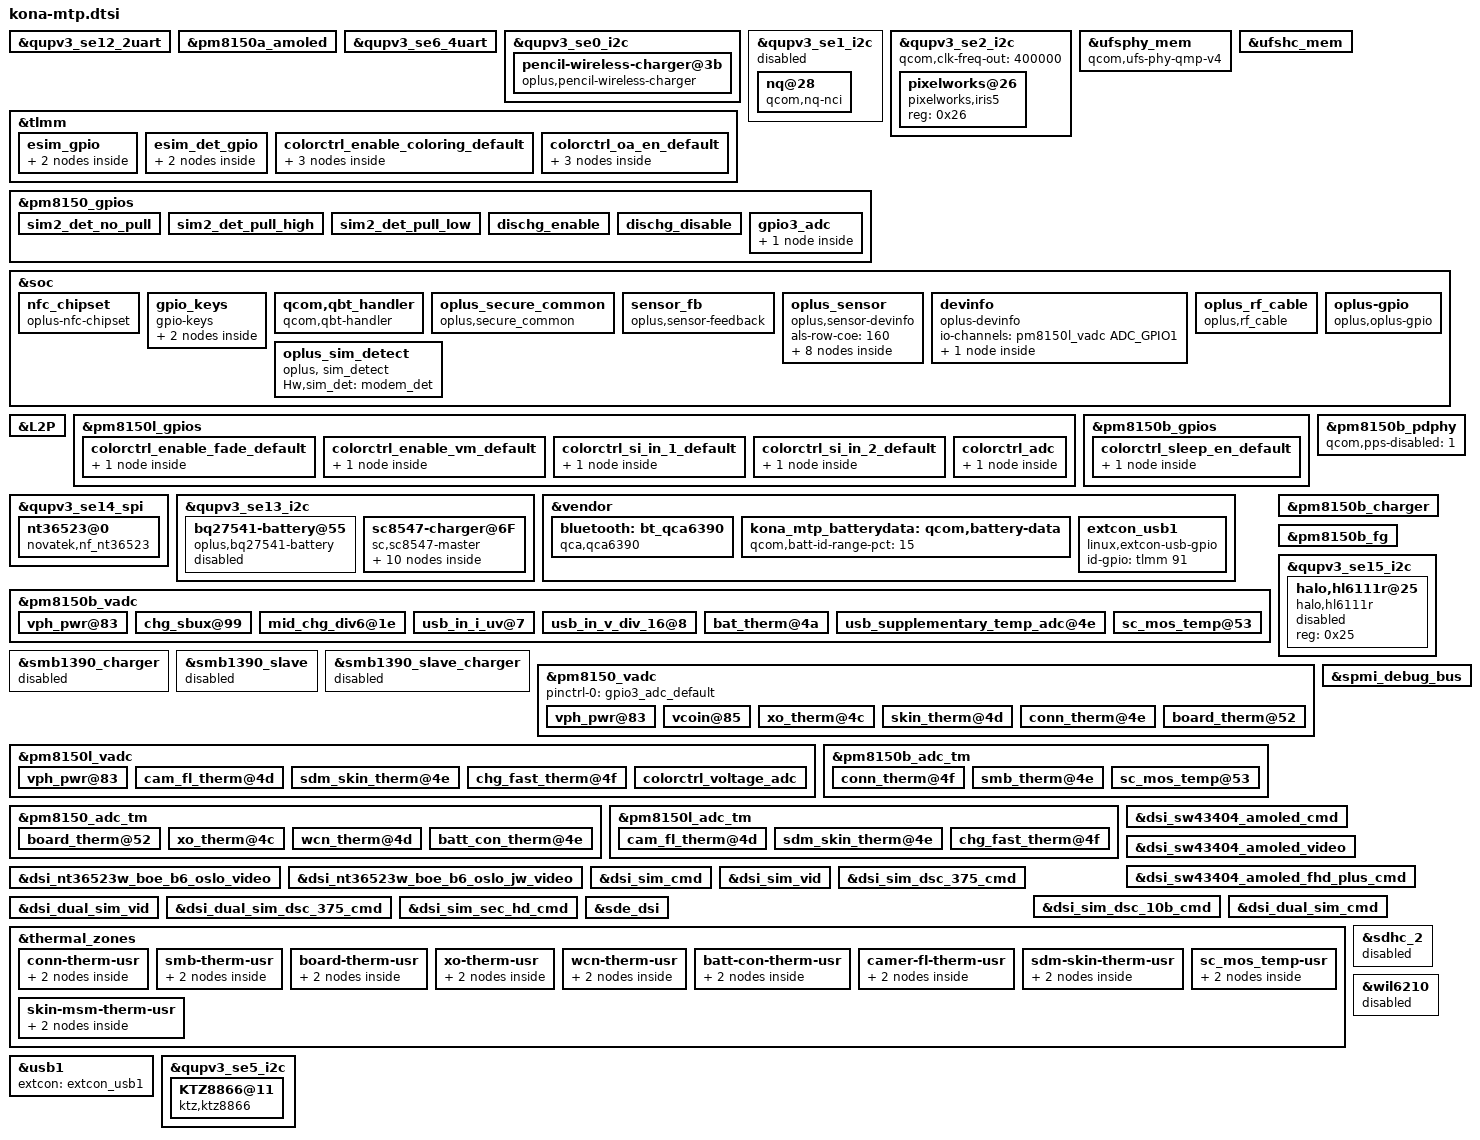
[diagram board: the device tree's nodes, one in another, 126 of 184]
#include <dt-bindings/gpio/gpio.h>
#include <dt-bindings/input/input.h>

#include "kona-pmic-overlay.dtsi"
#include "kona-sde-display.dtsi"
#include "camera/kona-camera-sensor-mtp.dtsi"
#include "kona-audio-overlay.dtsi"
#include "kona-thermal-overlay.dtsi"
#include "nt36523_tp_firmware.dtsi"
&qupv3_se12_2uart {
	status = "ok";
};

&pm8150a_amoled {
	status = "ok";
};

&qupv3_se6_4uart {
	status = "ok";
};
/* #ifdef OPLUS_ARCH_EXTENDS */
/* delete for audio pa
&dai_mi2s2 {
	qcom,msm-mi2s-tx-lines = <1>;
	pinctrl-names = "default", "sleep";
	pinctrl-0 = <&tert_mi2s_sck_active &tert_mi2s_ws_active
			&tert_mi2s_sd0_active>;
	pinctrl-1 = <&tert_mi2s_sck_sleep &tert_mi2s_ws_sleep
			&tert_mi2s_sd0_sleep>;
};
*/
/* #endif OPLUS_ARCH_EXTENDS */

&qupv3_se0_i2c {
	status = "ok";
	pencil-wireless-charger@3b {
		status = "ok";
		compatible = "oplus,pencil-wireless-charger";
		reg = <0x3b 0>;

		pinctrl-names = "idt_int_active", "idt_int_sleep", "idt_int_default",
						"vbat_en_active", "vbat_en_sleep", "vbat_en_default",
						"booster_en_active", "booster_en_sleep", "booster_en_default";

		pinctrl-0 = <&idt_int_active>;
		pinctrl-1 = <&idt_int_sleep>;
		pinctrl-2 = <&idt_int_default>;
		pinctrl-3 = <&vbat_en_active>;
		pinctrl-4 = <&vbat_en_sleep>;
		pinctrl-5 = <&vbat_en_default>;
		pinctrl-6 = <&booster_en_active>;
		pinctrl-7 = <&booster_en_sleep>;
		pinctrl-8 = <&booster_en_default>;

		qcom,idt_int-gpio = <&tlmm 31 0x00>;
		qcom,vbat_en-gpio = <&tlmm 33 0x00>;
		qcom,booster_en-gpio = <&tlmm 30 0x00>;

		qcom,ocp_threshold = <500>;
		qcom,ovp_threshold = <12000>;
		qcom,lvp_threshold = <4000>;
		qcom,pcop_threshold1 = <700>;
		qcom,pcop_threshold2 = <500>;
		qcom,fod_threshold = <400>;
		rx,soc_threshold = <90>;
	};
};

//#ifndef OPLUS_BUG_STABILITY
/*&qupv3_se1_i2c {
	status = "ok";
	qcom,clk-freq-out = <1000000>;
	#address-cells = <1>;
	#size-cells = <0>;
	nq@28 {
		compatible = "qcom,nq-nci";
		reg = <0x28>;
		qcom,nq-irq = <&tlmm 111 0x00>;
		qcom,nq-ven = <&tlmm 6 0x00>;
		qcom,nq-firm = <&tlmm 110 0x00>;
		qcom,nq-clkreq = <&tlmm 7 0x00>;
		interrupt-parent = <&tlmm>;
		interrupts = <111 0>;
		interrupt-names = "nfc_irq";
		pinctrl-names = "nfc_active", "nfc_suspend";
		pinctrl-0 = <&nfc_int_active &nfc_enable_active
				&nfc_clk_req_active>;
		pinctrl-1 = <&nfc_int_suspend &nfc_enable_suspend
				&nfc_clk_req_suspend>;
	};
};
*/
//#else /* OPLUS_BUG_STABILITY */
&qupv3_se1_i2c {
	status = "disabled";
	//#ifndef OPLUS_BUG_STABILITY
	//qcom,clk-freq-out = <1000000>;
	//#endif /* OPLUS_BUG_STABILITY */
	#address-cells = <1>;
	#size-cells = <0>;
	nq@28 {
		compatible = "qcom,nq-nci";
		reg = <0x28>;
		qcom,nq-irq = <&tlmm 111 0x00>;
		qcom,nq-ven = <&tlmm 83 0x00>;
		qcom,nq-firm = <&tlmm 110 0x00>;
		qcom,nq-clkreq = <&tlmm 7 0x00>;
		interrupt-parent = <&tlmm>;
		interrupts = <111 0>;
		interrupt-names = "nfc_irq";
		pinctrl-names = "nfc_active", "nfc_suspend";
		pinctrl-0 = <&nfc_int_active &nfc_enable_active
				&nfc_clk_req_active>;
		pinctrl-1 = <&nfc_int_suspend &nfc_enable_suspend
				&nfc_clk_req_suspend>;
	};
};
//#endif /* OPLUS_BUG_STABILITY */
&qupv3_se2_i2c {
       status = "ok";
       qcom,clk-freq-out = <400000>;
       pixelworks@26 {  //i2c: 22, i3c: 26
               status = "ok";
               compatible = "pixelworks,iris5";
               reg = <0x26>;
        };
};

&ufsphy_mem {
	compatible = "qcom,ufs-phy-qmp-v4";

	vdda-phy-supply = <&pm8150_l5>;
	vdda-phy-always-on;
	vdda-pll-supply = <&pm8150_l9>;
	vdda-phy-max-microamp = <89900>;
	vdda-pll-max-microamp = <18800>;

	status = "ok";
};

&ufshc_mem {
	vdd-hba-supply = <&ufs_phy_gdsc>;
	vdd-hba-fixed-regulator;
	vcc-supply = <&pm8150_l17>;
	vcc-voltage-level = <2504000 2950000>;
	vcc-low-voltage-sup;
	vccq-supply = <&pm8150_l6>;
	vccq2-supply = <&pm8150_s4>;
	vcc-max-microamp = <800000>;
	vccq-max-microamp = <800000>;
	vccq2-max-microamp = <800000>;

	qcom,vddp-ref-clk-supply = <&pm8150_l6>;
	qcom,vddp-ref-clk-max-microamp = <100>;
	qcom,vccq-parent-supply = <&pm8150a_s8>;
	qcom,vccq-parent-max-microamp = <210000>;

	status = "ok";
};

&tlmm {
	//#ifdef OPLUS_FEATRUE_ESIM
	esim_gpio: esim_gpio {
		mux {
			pins = "gpio67";
			function = "gpio";
		};
		config {
			pins = "gpio67";
			bias-disable; /* NO pull */
			drive-strength = <2>; /* 2 MA */
			output-low;
		};
	};

	esim_det_gpio: esim_det_gpio {
		mux {
			pins = "gpio70";
			function = "gpio";
		};
		config {
			pins = "gpio70";
			bias-disable; /* NO pull */
			drive-strength = <2>; /* 2 MA */
			output-high;
		};
	};
	//#endif /* OPLUS_FEATRUE_ESIM */
};

&pm8150_gpios {
	//#ifdef OPLUS_FEATRUE_DUAL_SIM_DETECT
	sim2_det_no_pull: sim2_det_no_pull {
			pins = "gpio1";
			function = "normal";
			input-enable;
			bias-disable;
	};

	sim2_det_pull_high: sim2_det_pull_high {
			pins = "gpio1";
			function = "normal";
			input-enable;
			bias-pull-up;
	};

	sim2_det_pull_low: sim2_det_pull_low {
			pins = "gpio1";
			function = "normal";
			input-enable;
			bias-pull-down;
	};
	//#endif OPLUS_FEATRUE_DUAL_SIM_DETECT
};

&soc {
	//#ifdef OPLUS_FEATURE_CONNFCSOFT
	nfc_chipset {
		compatible = "oplus-nfc-chipset";
		chipset-21027 = "SN100T";
                chipset-20351 = "SN100T";
                chipset-20163 = "SN100T";
	};
	//#endif /* OPLUS_FEATURE_CONNFCSOFT */

	gpio_keys {
		compatible = "gpio-keys";
		label = "gpio-keys";

		pinctrl-names = "default";
		//#ifdef OPLUS_FEATURE_TP_BASIC
		pinctrl-0 = <&key_vol_up_default &key_vol_down_default>;
		//#endif

		vol_up {
			label = "volume_up";
			gpios = <&pm8150_gpios 7 GPIO_ACTIVE_LOW>;
			linux,input-type = <1>;
			linux,code = <KEY_VOLUMEUP>;
			gpio-key,wakeup;
			debounce-interval = <15>;
			linux,can-disable;
		};
		//#ifdef OPLUS_FEATURE_TP_BASIC
		vol_down {
			label = "volume_down";
			gpios = <&pm8150_gpios  6 GPIO_ACTIVE_LOW>;
			linux,input-type = <1>;
			linux,code = <KEY_VOLUMEDOWN>;
			gpio-key,wakeup;
			debounce-interval = <15>;
			linux,can-disable;
		};
		//#endif
	};

	qcom,qbt_handler {
		compatible = "qcom,qbt-handler";
//#ifdef OPLUS_FEATURE_FINGERPRINT
		//qcom,ipc-gpio = <&tlmm 23 0>;
//#endif /*OPLUS_FEATURE_FINGERPRINT*/
//#ifndef OPLUS_FEATURE_CHG_BASIC
		//pinctrl-names = "default";
		//pinctrl-0 = <&key_home_default>;
		//qcom,finger-detect-gpio = <&pm8150_gpios 1 0>;
/*#endif*/
	};

	oplus_secure_common {
		compatible = "oplus,secure_common";
        oplus,sec_reg_num = <0x7805E8>;
        oplus,sec_en_anti_reg = <0x7801F4>;
        oplus,sec_override1_reg = <0x7860C0>;
        oplus,override1_en_value = <0x1>;
	};
	//#ifdef OPLUS_FEATURE_SENSOR_SMEM
	/*enum sensor_id { ACCEL,GYRO,MAG,LIGHT,PROXIMITY,SAR,CT,BAROMETER,SENSORS_NUM};*/
        sensor_fb: sensor_fb {
            compatible = "oplus,sensor-feedback";
            master-id  = <3>;
            smem-id    = <608>;
        };
	oplus_sensor {
		compatible = "oplus,sensor-devinfo";
		als-row-coe = <160>;
		/*enum {LSM6DSM = 0x01, BMI160 = 0x02, LSM6DS3 = 0x04,BMI260 = 0x08, LSM6DSO = 0x10};*/
		gsensor@0 {
			sensor-name = <0x20>;//ICM4X6XX
			sensor-direction = <7>;
			sensor-index = <0>;//source num
			sensor-type = <0>;//OPLUS_ACCEL
		};
		gsensor@1 {
			sensor-name = <0x8>;//BMI260
			sensor-direction = <1>;
			sensor-index = <1>;//source num
			sensor-type = <0>;//OPLUS_ACCEL
		};
		/* enum {AKM0991X = 0x01, MMC5603 = 0x02};*/
		msensor@0 {
			sensor-name = <0x1>;//AKM0991X
			sensor-direction = <0>;
			sensor-index = <0>;
			sensor-type = <2>;//MAG
			parameter-number= <18>;
			//sensor-parameter = <2>;//0-useless;other- to differ special parameter
			soft-mag-parameter = <9194 0 1530 0 117 1 1508 0 9538 0 220 1 1150 0 1311 1 10396 0>;//e00 sign e01 sign ...
		};
		msensor@1 {
			sensor-name = <0x2>;//MMC5603
			sensor-direction = <0>;
			sensor-index = <1>;
			sensor-type = <2>;//MAG
			parameter-number= <18>;
			soft-mag-parameter = <10000 0 0 0 0 0 0 0 10000 0 0 0 0 0 0 0 10000 0>;//e00 sign e01 sign ...

		};
		/* enum {tcs3408 = 0x01  stk37600 = 0x02} */
		cctsensor@0 {
			decoupled-driver = <1>; //0 - tcs3408 driver; 1 - oplus_cct driver
			sensor-name = <0x1>; //tcs3408
			sensor-index = <0>;
			sensor-type = <6>; //CCT
			bus-number = <5>;
			publish-sensors = <0x7>; //bit[0] - als, bit[1] - rgb, bit[2] - flicker
			is-ch-dri = <0>;
			timer-size = <25>; //ms
			fac-cali-sensor = <0x2>; //0x1 - als, 0x2 - rgb, 0x4, flicker
			para-matrix = <1>;
			algo-flag = <1>;
			fac-cali-again = <128>;
			first-again = <32>;
			first-atime = <50000>;
			atime = <100000>;
		};
		/*virtual sensor
		enum sensor_algo_id {
			PICKUP_DETECT,
			LUX_AOD,
			TP_GESTURE,
			FP_DISPLAY,
			FREE_FALL,
			CAMERA_PROTECT,
			SENSOR_ALGO_NUM
		}*/
		lux_aod {
			sensor-type = <1>; //LUX_AOD
			is-virtual-sensor;
			thrd-low = <12>;
			thrd-high = <50>;
			als-type = <1>; // 0 - ambient_light; 1 - wise_light
		};
		fp_display {
			sensor-type = <3>;//FP_DISPLAY
			is-virtual-sensor;
			prox-type = <0>; //  0 - proximity; 1 - proximity_fake
		};
		free_fall {
			sensor-type = <4>;//FREE_FALL
			is-virtual-sensor;
		};
	};
	//#endif /*OPLUS_FEATURE_SENSOR_SMEM*/
	
	//#ifdef OPLUS_FEATURE_TP_BASIC
	devinfo {
		compatible = "oplus-devinfo";
/*#ifdef OPLUS_FEATURE_TP_BASIC*/
		/*pinctrl-names = "active", "sleep";
		  pinctrl-0 = <&hw_id_active>;
		  pinctrl-1 = <&hw_id_sleep>;*/
/*endif OPLUS_FEATURE_TP_BASIC*/
		io-channels= <&pm8150l_vadc ADC_GPIO1>;
		io-channel-names= "vph_pwr_voltage_sub";

		main-sub {
			compatible = "hw-match, main-sub";
			use_pmic_adc;
			adc_ranges = <0 80
						81 180
						181 300
						301 420
						421 550
						551 650
						651 760
						761 850
						851 950
						951 1050
						1051 1150
						1151 1300>;
			aboard-patterns = <0 0 1 1>;

			/*main board*/
			match-projects = <21027 20163 20351 20352>;

			/*rf type*/
			//rf_match_support;
			//rf-patterns = <0>;
		};
/*#ifdef OPLUS_FEATURE_TP_BASIC*/
		/*device_0 {
			compatible = "hw, devices";
			label = "distribution";
			//hw-id0 = <&pm8150_gpios 1 0>;
			hw-combs = <1 0>;
			hw-names = "Standard", "Pro";
		};*/
/*endif OPLUS_FEATURE_TP_BASIC*/
	};

	//#ifdef OPLUS_FEATURE_TP_BASIC
	oplus_rf_cable {
		compatible = "oplus,rf_cable";
		interrupt-parent = <&tlmm>;
		rf_cable_support_num = <1>;
		rf,cable0-gpio = <&tlmm 84 0>;
		rf,cable-support-timer = <0>;
		pinctrl-names = "rf_cable_active";
		pinctrl-0 = <&rf_cable0_active>;
	};
	//#endif /* OPLUS_FEATURE_TP_BASIC */

	oplus_sim_detect {
		compatible = "oplus, sim_detect";
		Hw,sim_det = "modem_det";
	};

	//#ifdef OPLUS_FEATRUE_ESIM
	oplus-gpio {
		compatible = "oplus,oplus-gpio";
		pinctrl-names = "default", "sim2_det_no_pull", "sim2_det_pull_high", "sim2_det_pull_low";
		pinctrl-0 = <&esim_gpio &esim_det_gpio &sim2_det_no_pull>;
                pinctrl-1 = <&sim2_det_no_pull>;
                pinctrl-2 = <&sim2_det_pull_high>;
                pinctrl-3 = <&sim2_det_pull_low>;
		oplus,oplus-gpio-esim = <&tlmm 67 0>;
		oplus,oplus-esim-det = <&tlmm 70 0>;
                oplus,oplus-sim2-det = <&pm8150_gpios 1 0>;
                oplus,uim-reset-pin = "modem_solution";
	};
	//#endif /* OPLUS_FEATRUE_ESIM */
};

/*#ifdef OPLUS_FEATURE_TP_BASIC*/
&L2P {
	regulator-min-microvolt = <528000>;
	regulator-max-microvolt = <1504000>;
	qcom,min-dropout-voltage = <10000>;
};
&tlmm {
	colorctrl_enable_coloring_default{
		enable_coloring_default: enable_coloring_default {
			 mux {
				 pins = "gpio11";
				 function = "gpio";
			 };

			 config {
				 pins = "gpio11";
				 drive-strength = <8>;
				 bias-disable = <0>;
				 output-low;
			 };
		 };
	};
	colorctrl_oa_en_default{
		oa_en_default: oa_en_default {
			mux {
				pins = "gpio8";
				function = "gpio";
		       };

		       config {
			       pins = "gpio8";
			       drive-strength = <8>;
			       bias-disable = <0>;
			       output-low;
		       };
	       };
	};
};
&pm8150l_gpios {
        colorctrl_enable_fade_default {
                enable_fade_default: enable_fade_default {
                        pins = "gpio9";//GPIO 9
                        function = "normal";
                        bias-disable; //No Pull
                        power-source = <0>;
                        output-low; //digital output, no invert
                        qcom,drive-strength = <3>; //LOW strength
                        drive-push-pull;//CMOS
                };
        };
};
/*#endif OPLUS_FEATURE_TP_BASIC*/

//#ifdef OPLUS_FEATURE_TP_BASIC
&pm8150b_gpios {
    colorctrl_sleep_en_default {
        sleep_en_default: sleep_en_default {
					pins = "gpio5";//GPIO 5
					function = "normal";
					bias-disable; //No Pull
					power-source = <0>;
					output-low; //digital output, no invert
					qcom,drive-strength = <3>; //LOW strength
					drive-push-pull;//CMOS
        };
    };
};
&pm8150l_gpios {
	colorctrl_enable_vm_default {
		enable_vm_default: enable_vm_default {
			pins = "gpio9";//GPIO 9
			function = "normal";
			bias-disable; //No Pull
			power-source = <0>;
			output-low; //digital output, no invert
			qcom,drive-strength = <3>; //LOW strength
			drive-push-pull;//CMOS
		};
	};
	colorctrl_si_in_1_default {
		si_in_1_default: si_in_1_default {
			pins = "gpio8";//GPIO 8
			function = "normal";
			bias-disable; //No Pull
			power-source = <0>;
			output-low; //digital output, no invert
			qcom,drive-strength = <3>; //LOW strength
			drive-push-pull;//CMOS
		};
	};
	colorctrl_si_in_2_default {
		si_in_2_default: si_in_2_default {
			pins = "gpio11";//GPIO 11
			function = "normal";
			bias-disable; //No Pull
			power-source = <0>;
			output-low; //digital output, no invert
			qcom,drive-strength = <3>; //LOW strength
			drive-push-pull;//CMOS
		};
	};
	colorctrl_adc {
		colorctrl_adc_default: colorctrl_adc_default {
			pins = "gpio7"; /* GPIO 7 */
			function = "normal"; /* normal */
			bias-high-impedance; /* DISABLE GPIO7 for ADC*/
		};
	};
};
//#endif /* OPLUS_FEATURE_TP_BASIC */

/*&qupv3_se13_i2c {
	#address-cells = <1>;
	#size-cells = <0>;

	status = "ok";
	qcom,i2c-touch-active = "st,fts";

	st_fts@49 {
		compatible = "st,fts";
		reg = <0x49>;
		interrupt-parent = <&tlmm>;
		interrupts = <39 0x2008>;
		vdd-supply = <&pm8150a_l1>;
		avdd-supply = <&pm8150_l13>;
		pinctrl-names = "pmx_ts_active", "pmx_ts_suspend";
		pinctrl-0 = <&ts_active>;
		pinctrl-1 = <&ts_int_suspend &ts_reset_suspend>;
		st,irq-gpio = <&tlmm 39 0x2008>;
		st,reset-gpio = <&tlmm 38 0x00>;
		st,regulator_dvdd = "vdd";
		st,regulator_avdd = "avdd";
		st,x-flip = <1>;
		st,y-flip = <1>;
		panel = <&dsi_sw43404_amoled_cmd &dsi_sw43404_amoled_video
			 &dsi_sw43404_amoled_fhd_plus_cmd>;
	};
};
*/

&qupv3_se14_spi {
	status = "okay";
		nt36523@0 {
		status = "okay";
		compatible = "novatek,nf_nt36523";
		reg = <0>;
		chip-num = <1>;
		chip-name = "NT36523";
		project_id = <21027>;
		spi-max-frequency = <9600000>; //4800000,9600000,15000000,19200000
		interrupt-parent = <&tlmm>;
		interrupts = <39 0x0>;
		irq-gpio = <&tlmm 39 0x2002>;
               cs-gpio = <&tlmm 43 0x00>;
		// zsw bringup temp modify
		//reset-gpio = <&tlmm 53 0x00>;
		//lcd-reset-gpio = <&tlmm 85 0x00>;

		touchpanel,max-num-support = <10>;
		touchpanel,tx-rx-num = <32 50>;
		touchpanel,panel-coords = <1600 2560>;
		touchpanel,display-coords = <1600 2560>;
		touchpanel,touchmajor-limit = <0 54>;

		touchpanel,pen-tx-rx-num = <4 6>;
		touchpanel,pen-panel-coords = <3200 5120>;
		touchpanel,pen-max-pressure = <4096>;
		touchpanel,pen-max-tilt = <60 60>;
		touchpanel,msecs-to-jiffies-time = <100>;
		tp_type = <3>;
		platform_support_project = <21027>;
		platform_support_project_dir = <21027>;
		platform_support_commandline = "default_commandline";
		platform_support_project_commandline = "default_commandline";
		platform_support_project_external_name = "FA261";
		vid_len = <7>;

		pinctrl-names = "default";
		pinctrl-0 = <&ts_int_active>;

		incell_screen;
        //       iovcc_shutdown_support;
		fw_edge_limit_support;
		black_gesture_support;
		charger_pump_support;
		headset_pump_support;
		esd_handle_support;
		black_gesture_test_support;
		game_switch_support;
		noflash_support;
		lcd_trigger_load_tp_fw_support;
		smart_gesture_support;
		pressure_report_support;
		pen_support;
		irq_need_dev_resume_ok;
		fw_update_app_support;
		health_monitor_v2_support;
		fw_update_in_probe_with_headfile;
		black_gesture_indep_support;
		touchpanel,button-type = <4>;
	};
};

//#ifdef OPLUS_FEATURE_TP_BASIC
&qupv3_se13_i2c {
	status = "okay";
	bq27541-battery@55 {
		status = "disabled";
		compatible = "oplus,bq27541-battery";
		reg = <0x55>;
		qcom,modify-soc-smooth;
		qcom,modify-soc-calibration;
		qcom,batt_bq28z610;
		//qcom,bq28z610_need_balancing;
	};

	sc8547-charger@6F{
		status = "okay";
		compatible = "sc,sc8547-master";
		reg = <0x6F>;

		qcom,irq_gpio = <&tlmm 51 0x00>;

		pinctrl-names = "switch1_act_switch2_act", "switch1_sleep_switch2_sleep",
				"charging_inter_active", "charging_inter_sleep";
		pinctrl-0 = <&charging_switch1_active>;
		pinctrl-1 = <&charging_switch1_sleep>;
		pinctrl-2 = <&charging_inter_active>;
		pinctrl-3 = <&charging_inter_sleep>;

		qcom,charging_switch1-gpio = <&tlmm 82 0x00>;

		qcom,voocphy_current_default = <30>;

		qcom,svooc_cool_down_current_limit = <100 20 20 20 30 40 50 60 70 80 90 100>;
		qcom,vooc_cool_down_current_limit = <60 20 20 20 30 40 50 60>;

		qcom,fastchg_timeout_time_init = <173000>;
		qcom,vooc_little_cold_full_voltage = <4435>;
		qcom,vooc_cool_full_voltage = <4435>;
		qcom,vooc_warm_full_voltage = <4130>;
		qcom,vooc_1time_full_voltage = <4470>;
		qcom,vooc_ntime_full_voltage = <4470>;
		qcom,low_curr_full_t1 = <120>;
		qcom,low_curr_full_t2 = <350>;
		qcom,low_curr_full_t3 = <430>;
		qcom,range1_low_curr_full = <1150 4470
						1050 4465
						950 4450
						850 4450
						750 4450>;
		qcom,range2_low_curr_full = <1550 4470
						1450 4465
						1350 4450
						1250 4450
						1150 4450>;

		qcom,vooc_multistep_initial_batt_temp = <1000>;
		qcom,vooc_little_cool_temp = <160>;
		qcom,vooc_cool_temp = <120>;
		qcom,vooc_little_cold_temp = <50>;
		qcom,vooc_normal_low_temp = <250>;
		qcom,vooc_strategy_normal_current = <60>;
		qcom,vooc_normal_to_little_cool_current = <60>;
		qcom,vooc_batt_over_high_temp = <510>;
		qcom,vooc_batt_over_low_temp = <0>;
		qcom,vooc-high-temp = <500>;
		qcom,vooc-low-soc = <0>;
		qcom,vooc-high-soc = <90>;
		qcom,vooc-normal-high-temp = <430>;
		qcom,vooc-warm-allow-vol = <4000>;
		qcom,vooc-warm-allow-soc = <50>;

		qcom,vooc_strategy1_batt_high_temp0 = <385>;
		qcom,vooc_strategy1_batt_high_temp1 = <395>;
		qcom,vooc_strategy1_batt_high_temp2 = <420>;
		qcom,vooc_strategy1_batt_low_temp2 = <410>;
		qcom,vooc_strategy1_batt_low_temp1 = <385>;
		qcom,vooc_strategy1_batt_low_temp0 = <375>;

		qcom,vooc_strategy1_high_current0 = <60>;
		qcom,vooc_strategy1_high_current1 = <60>;
		qcom,vooc_strategy1_high_current2 = <50>;
		qcom,vooc_strategy1_low_current2 = <50>;
		qcom,vooc_strategy1_low_current1 = <60>;
		qcom,vooc_strategy1_low_current0 = <60>;

		qcom,voocphy_ibat_over_current = <7500>;
		qcom,voocphy_cp_max_ibus = <3500>;

		svooc_batt_sys_curve = <0 0 1 1 1 1 0	// 3000mA
					0 0 0 0 0 0 1	// 3414mV
					0 0 1 0 1 0 0	// 2000mA
					1 1 1 0 0 1 0	// 4550mV
					0 0 0 1 0 1 0	// 1000mA
					1 1 1 0 0 1 0>;	// 4550mV

		vooc_batt_sys_curve =  <0 0 1 1 1 1 0	// 3000mA
					0 0 0 0 0 0 1	// 3414mV
					0 0 1 0 1 0 0	// 2000mA
					1 1 1 0 0 1 0	// 4550mV
					0 0 0 1 0 1 0	// 1000mA
					1 1 1 0 0 1 0>;	// 4550mV

		svooc_charge_strategy {
			strategy_soc_0_to_50 {
				strategy_temp_little_cold =	<4180 18 0 0 0
								 4435 10 1 0 0>;
				strategy_temp_cool =   <4425 18 0 0 0
								 4425 14 0 0 0
								 4435 10 1 0 0>;
				strategy_temp_little_cool = 	<4460 25 0 0 0
								 4460 20 0 0 0
								 4460 15 0 0 0
								 4470 10 1 0 0>;
				strategy_temp_normal_low =	<4460 30 0 1200 0
								 4460 25 0 1200 0
								 4460 23 0 0 0
								 4460 20 0 0 0
								 4460 15 0 0 0
								 4470 10 1 0 0>;
				strategy_temp_normal_high =	<4460 30 0 1200 0
								 4460 25 0 1200 0
								 4460 23 0 0 0
								 4460 20 0 0 0
								 4460 15 0 0 0
								 4470 10 1 0 0>;
				strategy_temp_warm = <4130 20 1 0 0>;
			};

			strategy_soc_50_to_75 {
				strategy_temp_little_cold =	<4180 18 0 0 0
								 4435 10 1 0 0>;
				strategy_temp_cool =		<4425 18 0 0 0
								 4425 14 0 0 0
								 4435 10 1 0 0>;
				strategy_temp_little_cool =	<4460 25 0 0 0
								 4460 20 0 0 0
								 4460 15 0 0 0
								 4470 10 1 0 0>;
				strategy_temp_normal_low =	<4460 25 0 1200 0
								 4460 23 0 0 0
								 4460 20 0 0 0
								 4460 15 0 0 0
								 4470 10 1 0 0>;
				strategy_temp_normal_high =	<4460 25 0 1200 0
								 4460 23 0 0 0
								 4460 20 0 0 0
								 4460 15 0 0 0
								 4470 10 1 0 0>;
			};

			strategy_soc_75_to_85 {
				strategy_temp_little_cold = <4435 10 1 0 0>;
				strategy_temp_cool =		<4435 10 1 0 0>;
				strategy_temp_little_cool =	<4470 10 1 0 0>;
				strategy_temp_normal_low =	<4460 15 0 0 0
								4470 10 1 0 0>;
				strategy_temp_normal_high =	<4460 15 0 0 0
								4470 10 1 0 0>;
			};

			strategy_soc_85_to_90 {
				strategy_temp_little_cold = <4435 10 1 0 0>;
				strategy_temp_cool =		<4435 10 1 0 0>;
				strategy_temp_little_cool =	<4470 10 1 0 0>;
				strategy_temp_normal_low =	<4470 10 1 0 0>;
				strategy_temp_normal_high =	<4470 10 1 0 0>;
			};
		};

		vooc_charge_strategy {
			strategy_soc_0_to_50 {
				strategy_temp_little_cold = <4180 30 0 0 0
								4435 20 1 0 0>;
				strategy_temp_cool = <4425 30 0 0 0
								4435 20 1 0 0>;
				strategy_temp_little_cool =	<4460 30 0 0 0
								4470 20 1 0 0>;
				strategy_temp_normal_low =	<4460 30 0 0 0
								4470 20 1 0 0>;
				strategy_temp_normal_high =	<4460 30 0 0 0
								4470 20 1 0 0>;
				strategy_temp_warm = <4130 20 1 0 0>;
			};

			strategy_soc_50_to_75 {
				strategy_temp_little_cold =	<4180 30 0 0 0
								4435 20 1 0 0>;
				strategy_temp_cool = <4425 30 0 0 0
								4435 20 1 0 0>;
				strategy_temp_little_cool =	<4460 30 0 0 0
								4470 20 1 0 0>;
				strategy_temp_normal_low = <4460 30 0 0 0
								4470 00 1 0 0>;
				strategy_temp_normal_high =	<4460 30 0 0 0
								4470 00 1 0 0>;
			};

			strategy_soc_75_to_85 {
				strategy_temp_little_cold =	<4435 20 1 0 0>;
				strategy_temp_cool = 		<4435 20 1 0 0>;
				strategy_temp_little_cool =	<4470 20 1 0 0>;
				strategy_temp_normal_low = 	<4460 30 0 0 0
								4470 20 1 0 0>;
				strategy_temp_normal_high =<4460 30 0 0 0
								4470 20 1 0 0>;
			};

			strategy_soc_85_to_90 {
				strategy_temp_little_cold =	<4435 20 1 0 0>;
				strategy_temp_cool =		<4435 20 1 0 0>;
				strategy_temp_little_cool =	<4470 20 1 0 0>;
				strategy_temp_normal_low =	<4470 20 1 0 0>;
				strategy_temp_normal_high =	<4470 20 1 0 0>;
			};
		};
	};
};
//#endif /*OPLUS_FEATURE_TP_BASIC*/

&vendor {
	bluetooth: bt_qca6390 {
		compatible = "qca,qca6390";
		pinctrl-names = "default";
		pinctrl-0 = <&bt_en_sleep>;
		qca,bt-reset-gpio = <&tlmm 21 0>; /* BT_EN */
		qca,wl-reset-gpio = <&tlmm 20 0>; /* WL_EN */
		qca,bt-vdd-aon-supply = <&pm8150_s6>;
//#ifdef OPLUS_ARCH_EXTENDS
		//qca,bt-vdd-dig-supply = <&pm8009_s2>;
//#endif /* OPLUS_ARCH_EXTENDS */
		qca,bt-vdd-rfa1-supply = <&pm8150_s5>;
		qca,bt-vdd-rfa2-supply = <&pm8150a_s8>;
//#ifdef OPLUS_FEATURE_FINGERPRINT
		//qca,bt-vdd-asd-supply = <&pm8150_l16>;
//#endif /*OPLUS_FEATURE_FINGERPRINT*/

		qca,bt-vdd-aon-voltage-level = <950000 950000>;
//#ifdef OPLUS_ARCH_EXTENDS
		//qca,bt-vdd-dig-voltage-level = <950000 952000>;
//#endif /* OPLUS_ARCH_EXTENDS */
		qca,bt-vdd-rfa1-voltage-level = <1900000 1900000>;
		qca,bt-vdd-rfa2-voltage-level = <1350000 1350000>;
		qca,bt-vdd-asd-voltage-level = <3024000 3304000>;

		qca,bt-vdd-asd-current-level = <10000>;
	};

	kona_mtp_batterydata: qcom,battery-data {
		qcom,batt-id-range-pct = <15>;
		#include "fg-gen4-batterydata-alium-8360mah.dtsi"
	};

	extcon_usb1: extcon_usb1 {
		compatible = "linux,extcon-usb-gpio";
//#ifndef OPLUS_FEATURE_CHG_BASIC
		//vbus-gpio = <&pm8150_gpios 10 GPIO_ACTIVE_HIGH>;
/*#endif*/
		id-gpio = <&tlmm 91 GPIO_ACTIVE_HIGH>;
//#ifndef OPLUS_FEATURE_CHG_BASIC
		//vbus-out-gpio = <&pm8150_gpios 9 GPIO_ACTIVE_HIGH>;

		//pinctrl-names = "default";
		//pinctrl-0 = <&usb2_vbus_det_default
		//	     &usb2_id_det_default
		//	     &usb2_vbus_boost_default>;
/*#endif*/
	};
};

&pm8150b_pdphy {
	qcom,pps-disabled = <1>;
};

&pm8150b_vadc {
	#address-cells = <1>;
	#size-cells = <0>;

	vph_pwr@83 {
		reg = <ADC_VPH_PWR>;
		label = "vph_pwr";
		qcom,pre-scaling = <1 3>;
	};

	chg_sbux@99 {
		reg = <ADC_SBUx>;
		label = "chg_sbux";
		qcom,pre-scaling = <1 3>;
	};

	mid_chg_div6@1e {
		reg = <ADC_MID_CHG_DIV6>;
		label = "chg_mid";
		qcom,pre-scaling = <1 6>;
	};

	usb_in_i_uv@7 {
		reg = <ADC_USB_IN_I>;
		label = "usb_in_i_uv";
		qcom,pre-scaling = <1 1>;
	};

	usb_in_v_div_16@8 {
		reg = <ADC_USB_IN_V_16>;
		label = "usb_in_v_div_16";
		qcom,pre-scaling = <1 16>;
	};

	bat_therm@4a {
		reg = <ADC_BAT_THERM_PU2>;
		label = "bat_therm";
		qcom,hw-settle-time = <200>;
		qcom,pre-scaling = <1 1>;
	};
//#ifdef OPLUS_FEATURE_CHG_BASIC
	usb_supplementary_temp_adc@4e {
		reg = <ADC_AMUX_THM2_PU2>;
		label = "usb_supplementary_temp_adc";
		qcom,ratiometric;
		qcom,pre-scaling = <1 1>;
	};

	sc_mos_temp@53 { //GPIO12
		reg = <ADC_GPIO2_PU2>;
		label = "sc_mos_temp";
		qcom,ratiometric;
		qcom,hw-settle-time = <200>;
		qcom,pre-scaling = <1 1>;
	};
//#endif

};
&pm8150b_charger {
	status = "ok";
	qcom,sec-charger-config = <1>;
	qcom,auto-recharge-soc = <98>;
	io-channels = <&pm8150b_vadc ADC_MID_CHG_DIV6>,
		      <&pm8150b_vadc ADC_USB_IN_I>,
		      <&pm8150b_vadc ADC_SBUx>,
		      <&pm8150b_vadc ADC_VPH_PWR>,
		      <&pm8150b_vadc ADC_CHG_TEMP>,
			  //<&pm8150b_vadc ADC_GPIO3>,
			  <&pm8150b_vadc ADC_AMUX_THM3_PU2>,
			  <&pm8150b_vadc ADC_AMUX_THM2_PU2>,
			  <&pm8150_vadc ADC_GPIO1_PU2>,
			  <&pm8150_vadc ADC_AMUX_THM2_PU2>;
//#else
		      //<&pm8150b_vadc ADC_CHG_TEMP>;
//#endif
	io-channel-names = "mid_voltage",
			   "usb_in_current",
			   "sbux_res",
			   "vph_voltage",
			   "chg_temp",
			   //"chgID_voltage_adc",
			   "usb_temp_adc",
			   "usb_supplementary_temp_adc",
			   "board_therm",
			   "btb_temp_therm";
//#else
				///"chg_temp";
//#endif
	qcom,battery-data = <&kona_mtp_batterydata>;
	qcom,step-charging-enable;
	qcom,sw-jeita-enable;
	qcom,wd-bark-time-secs = <16>;
	qcom,suspend-input-on-debug-batt;
	qcom,fcc-stepping-enable;
	qcom,smb-internal-pull-kohm = <0>;
	qcom,adc-check-pulse;
	qcom,soc-ready-check;
};

&pm8150b_fg {
//#ifndef OPLUS_FEATURE_CHG_BASIC
	status = "ok";
//#else
//	status = "disabled";
///#endif
	qcom,battery-data = <&kona_mtp_batterydata>;
	qcom,hold-soc-while-full;
	qcom,linearize-soc;
	qcom,five-pin-battery;
	qcom,cl-wt-enable;
	qcom,soc-scale-mode-en;
	qcom,fg-force-load-profile;
	qcom,multi-profile-load;
	qcom,force-calib-level = <130>;
	qcom,fg-cutoff-voltage = <3380>;
	qcom,fg-sys-term-current = <(-475)>;
	qcom,soc-scale-mode-en;
	qcom,soc-scale-vbatt-mv = <3850>;
	qcom,ki-coeff-soc-dischg = <30 80 100>;
	qcom,ki-coeff-hi-dischg = <62 62 62>;
	qcom,ki-coeff-med-dischg = <122 122 122>;
	qcom,ki-coeff-low-dischg = <183 183 183>;
	qcom,ki-coeff-dischg-low-med-thresh-ma = <60>;
	qcom,ki-coeff-dischg-med-hi-thresh-ma = <500>;
	/* ESR fast calibration */
	qcom,fg-esr-timer-chg-fast = <0 7>;
	qcom,fg-esr-timer-dischg-fast = <0 7>;
	qcom,fg-esr-timer-chg-slow = <0 96>;
	qcom,fg-esr-timer-dischg-slow = <0 96>;
	qcom,fg-esr-cal-soc-thresh = <26 230>;
	qcom,fg-esr-cal-temp-thresh = <10 40>;
	io-channels = <&pm8150b_vadc ADC_BAT_ID_PU2>,
					<&pm8150b_vadc ADC_BAT_THERM_PU2>;
	io-channel-names = "batt_id",
						"batt-therm";
};

&qupv3_se15_i2c {
	#address-cells = <1>;
	#size-cells = <0>;
#include "smb1390.dtsi"

	halo,hl6111r@25 {
		compatible = "halo,hl6111r";
		reg = <0x25>;
		status = "disabled";
	};
};

/*
&smb1390 {
	pinctrl-names = "default";
	pinctrl-0 = <&smb_stat_default>;
	status = "ok";
};
*/
//#endif

&smb1390_charger {
	io-channels = <&pm8150b_vadc ADC_AMUX_THM2>;
	io-channel-names = "cp_die_temp";
	qcom,parallel-output-mode = <2>;
	qcom,min-ilim-ua = <750000>;
	status = "disabled";
};

&smb1390_slave {
	status = "disabled";
};

&smb1390_slave_charger {
	status = "disabled";
};

&pm8150_vadc {
	#address-cells = <1>;
	#size-cells = <0>;
	pinctrl-names = "gpio3_adc_default";
	pinctrl-0 = <&gpio3_adc_default>;

	vph_pwr@83 {
		reg = <ADC_VPH_PWR>;
		label = "vph_pwr";
		qcom,pre-scaling = <1 3>;
	};

	vcoin@85 {
		reg = <ADC_VCOIN>;
		label = "vcoin";
		qcom,pre-scaling = <1 3>;
	};

	xo_therm@4c {
		reg = <ADC_XO_THERM_PU2>;
		label = "xo_therm";
		qcom,ratiometric;
		qcom,hw-settle-time = <200>;
		qcom,pre-scaling = <1 1>;
	};

	skin_therm@4d {
		reg = <ADC_AMUX_THM1_PU2>;
		label = "skin_therm";
		qcom,ratiometric;
		qcom,hw-settle-time = <200>;
		qcom,pre-scaling = <1 1>;
	};

	conn_therm@4e {
		reg = <ADC_AMUX_THM2_PU2>;
		label = "conn_therm";
		qcom,ratiometric;
		qcom,hw-settle-time = <200>;
		qcom,pre-scaling = <1 1>;
	};
	board_therm@52 {
		reg = <ADC_GPIO1_PU2>;
		label = "board_therm";
		qcom,ratiometric;
		qcom,hw-settle-time = <200>;
		qcom,pre-scaling = <1 1>;
	};
};

&pm8150l_vadc {
	#address-cells = <1>;
	#size-cells = <0>;

	vph_pwr@83 {
		reg = <ADC_VPH_PWR>;
		label = "vph_pwr";
		qcom,pre-scaling = <1 3>;
	};
	cam_fl_therm@4d {
		reg = <ADC_AMUX_THM1_PU2>;
		label = "cam_fl_therm";
		qcom,ratiometric;
		qcom,hw-settle-time = <200>;
		qcom,pre-scaling = <1 1>;
	};

	sdm_skin_therm@4e {
		reg = <ADC_AMUX_THM2_PU2>;
		label = "sdm_skin_therm";
		qcom,ratiometric;
		qcom,hw-settle-time = <200>;
		qcom,pre-scaling = <1 1>;
	};

	chg_fast_therm@4f {
		reg = <ADC_AMUX_THM3_PU2>;
		label = "chg_fast_therm";
		qcom,ratiometric;
		qcom,hw-settle-time = <200>;
		qcom,pre-scaling = <1 1>;
	};

/*#ifdef OPLUS_FEATURE_TP_BASIC*/
	colorctrl_voltage_adc {
		reg = <ADC_GPIO3_DIV3>;
		label = "colorctrl_voltage_adc";
		qcom,ratiometric;
		qcom,hw-settle-time = <200>;
		qcom,avg-samples = <2>;
		qcom,pre-scaling = <1 3>;
	};
/*#endif OPLUS_FEATURE_TP_BASIC*/
};

&pm8150b_adc_tm {
	#address-cells = <1>;
	#size-cells = <0>;

	io-channels = <&pm8150b_vadc ADC_GPIO2_PU2>,
			<&pm8150b_vadc ADC_AMUX_THM3_PU2>,
			<&pm8150b_vadc ADC_AMUX_THM2_PU2>;

	conn_therm@4f {
		reg = <ADC_AMUX_THM3_PU2>;
		qcom,ratiometric;
		qcom,hw-settle-time = <200>;
		qcom,pre-scaling = <1 1>;
	};
	smb_therm@4e {
		reg = <ADC_AMUX_THM2_PU2>;
		qcom,ratiometric;
		qcom,hw-settle-time = <200>;
	};
	sc_mos_temp@53 {   //GPIO12
		reg = <ADC_GPIO2_PU2>;
		qcom,ratiometric;
		qcom,hw-settle-time = <200>;
	};
};

&pm8150_adc_tm {
	#address-cells = <1>;
	#size-cells = <0>;

	io-channels = <&pm8150_vadc ADC_GPIO1_PU2>,
			<&pm8150_vadc ADC_XO_THERM_PU2>,
			<&pm8150_vadc ADC_AMUX_THM1_PU2>,
			<&pm8150_vadc ADC_AMUX_THM2_PU2>;

	board_therm@52 {
		reg = <ADC_GPIO1_PU2>;
		qcom,ratiometric;
		qcom,hw-settle-time = <200>;
	};

	xo_therm@4c {
		reg = <ADC_XO_THERM_PU2>;
		qcom,ratiometric;
		qcom,hw-settle-time = <200>;
	};

	wcn_therm@4d {
		reg = <ADC_AMUX_THM1_PU2>;
		qcom,ratiometric;
		qcom,hw-settle-time = <200>;
	};

	batt_con_therm@4e {
		reg = <ADC_AMUX_THM2_PU2>;
		qcom,ratiometric;
		qcom,hw-settle-time = <200>;
	};
};

&pm8150l_adc_tm {
	#address-cells = <1>;
	#size-cells = <0>;
		io-channels = <&pm8150l_vadc ADC_AMUX_THM1_PU2>,
			<&pm8150l_vadc ADC_AMUX_THM2_PU2>,
			<&pm8150l_vadc ADC_AMUX_THM3_PU2>;
/*change caiqinghua_wt  2021/09/09 NTC_bringup*/
	cam_fl_therm@4d {
		reg = <ADC_AMUX_THM1_PU2>;
		qcom,ratiometric;
		qcom,hw-settle-time = <200>;
	};

	sdm_skin_therm@4e {
		reg = <ADC_AMUX_THM2_PU2>;
		qcom,ratiometric;
		qcom,hw-settle-time = <200>;
	};

	chg_fast_therm@4f {
		reg = <ADC_AMUX_THM3_PU2>;
		qcom,ratiometric;
		qcom,hw-settle-time = <200>;
	};
};

&spmi_debug_bus {
	status = "ok";
};

&dsi_sw43404_amoled_cmd {
	qcom,panel-supply-entries = <&dsi_panel_pwr_supply>;
	qcom,mdss-dsi-bl-pmic-control-type = "bl_ctrl_dcs";
	qcom,mdss-dsi-bl-min-level = <1>;
	qcom,mdss-dsi-bl-max-level = <1023>;
	qcom,mdss-brightness-max-level = <255>;
	qcom,platform-te-gpio = <&tlmm 66 0>;
	qcom,platform-reset-gpio = <&tlmm 75 0>;
	qcom,mdss-dsi-panel-test-pin = <&tlmm 46 0>;
};

&dsi_sw43404_amoled_video {
	qcom,panel-supply-entries = <&dsi_panel_pwr_supply>;
	qcom,mdss-dsi-bl-pmic-control-type = "bl_ctrl_dcs";
	qcom,mdss-dsi-bl-min-level = <1>;
	qcom,mdss-dsi-bl-max-level = <1023>;
	qcom,mdss-brightness-max-level = <255>;
	qcom,platform-reset-gpio = <&tlmm 75 0>;
	qcom,mdss-dsi-panel-test-pin = <&tlmm 46 0>;
};

&dsi_sw43404_amoled_fhd_plus_cmd {
	qcom,panel-supply-entries = <&dsi_panel_pwr_supply>;
	qcom,mdss-dsi-bl-pmic-control-type = "bl_ctrl_dcs";
	qcom,mdss-dsi-bl-min-level = <1>;
	qcom,mdss-dsi-bl-max-level = <1023>;
	qcom,mdss-brightness-max-level = <255>;
	qcom,platform-te-gpio = <&tlmm 66 0>;
	qcom,platform-reset-gpio = <&tlmm 75 0>;
	qcom,mdss-dsi-panel-test-pin = <&tlmm 46 0>;
};
&dsi_nt36523w_boe_b6_oslo_video {
		qcom,panel-supply-entries = <&dsi_panel_pwr_supply>;
		qcom,mdss-dsi-bl-pmic-control-type = "bl_ctrl_external";
		qcom,mdss-dsi-bl-min-level = <10>;
		qcom,mdss-dsi-bl-max-level = <2047>;    // 11bit
		qcom,mdss-brightness-max-level = <2047>;
		qcom,mdss-brightness-normal-max-level = <2047>;
		qcom,mdss-dsi-bl-normal-max-level = <2047>;
		qcom,mdss-brightness-default-level = <1600>;
		qcom,platform-te-gpio = <&tlmm 66 0>;
		qcom,platform-reset-gpio = <&tlmm 75 0>;
		qcom,platform-tp-cs-gpio = <&tlmm 43 0>;
};
&dsi_nt36523w_boe_b6_oslo_jw_video {
		qcom,panel-supply-entries = <&dsi_panel_pwr_supply>;
		qcom,mdss-dsi-bl-pmic-control-type = "bl_ctrl_external";
		qcom,mdss-dsi-bl-min-level = <10>;
		qcom,mdss-dsi-bl-max-level = <2047>;    // 11bit
		qcom,mdss-brightness-max-level = <2047>;
		qcom,mdss-brightness-normal-max-level = <2047>;
		qcom,mdss-dsi-bl-normal-max-level = <2047>;
		qcom,mdss-brightness-default-level = <1600>;
		qcom,platform-te-gpio = <&tlmm 66 0>;
		qcom,platform-reset-gpio = <&tlmm 75 0>;
		qcom,platform-tp-cs-gpio = <&tlmm 43 0>;
};
&dsi_sim_cmd {
	qcom,panel-supply-entries = <&dsi_panel_pwr_supply>;
	qcom,mdss-dsi-bl-pmic-control-type = "bl_ctrl_dcs";
	qcom,platform-reset-gpio = <&tlmm 75 0>;
};

&dsi_sim_vid {
	qcom,panel-supply-entries = <&dsi_panel_pwr_supply>;
	qcom,mdss-dsi-bl-pmic-control-type = "bl_ctrl_dcs";
	qcom,platform-reset-gpio = <&tlmm 75 0>;
};

&dsi_sim_dsc_375_cmd {
	qcom,panel-supply-entries = <&dsi_panel_pwr_supply>;
	qcom,mdss-dsi-bl-pmic-control-type = "bl_ctrl_dcs";
	qcom,platform-reset-gpio = <&tlmm 75 0>;
};

&dsi_sim_dsc_10b_cmd {
	qcom,panel-supply-entries = <&dsi_panel_pwr_supply>;
	qcom,mdss-dsi-bl-pmic-control-type = "bl_ctrl_dcs";
	qcom,platform-reset-gpio = <&tlmm 75 0>;
};

&dsi_dual_sim_cmd {
	qcom,panel-supply-entries = <&dsi_panel_pwr_supply>;
	qcom,mdss-dsi-bl-pmic-control-type = "bl_ctrl_dcs";
	qcom,platform-reset-gpio = <&tlmm 75 0>;
};

&dsi_dual_sim_vid {
	qcom,mdss-dsi-bl-pmic-control-type = "bl_ctrl_dcs";
	qcom,platform-reset-gpio = <&tlmm 75 0>;
};

&dsi_dual_sim_dsc_375_cmd {
	qcom,panel-supply-entries = <&dsi_panel_pwr_supply>;
	qcom,mdss-dsi-bl-pmic-control-type = "bl_ctrl_dcs";
	qcom,platform-reset-gpio = <&tlmm 75 0>;
};

&dsi_sim_sec_hd_cmd {
	qcom,panel-supply-entries = <&dsi_panel_pwr_supply>;
	qcom,panel-sec-supply-entries = <&dsi_panel_pwr_supply>;
	qcom,mdss-dsi-bl-pmic-control-type = "bl_ctrl_dcs";
	qcom,mdss-dsi-sec-bl-pmic-control-type = "bl_ctrl_dcs";
	qcom,mdss-dsi-bl-min-level = <1>;
	qcom,mdss-dsi-bl-max-level = <1023>;
	qcom,platform-reset-gpio = <&tlmm 75 0>;
	qcom,platform-sec-reset-gpio = <&tlmm 128 0>;
};
&sde_dsi {
	qcom,dsi-default-panel = <&dsi_oplus19065_samsung_1440_3168_dsc_cmd>;
};

&thermal_zones {
	conn-therm-usr {
		polling-delay-passive = <0>;
		polling-delay = <0>;
		thermal-governor = "user_space";
		thermal-sensors = <&pm8150b_adc_tm ADC_AMUX_THM3_PU2>;
		wake-capable-sensor;
		trips {
			active-config0 {
				temperature = <125000>;
				hysteresis = <1000>;
				type = "passive";
			};
		};
	};

	smb-therm-usr {
		polling-delay-passive = <0>;
		polling-delay = <0>;
		thermal-governor = "user_space";
		thermal-sensors = <&pm8150b_adc_tm ADC_AMUX_THM2_PU2>;
		wake-capable-sensor;
		trips {
			active-config0 {
				temperature = <125000>;
				hysteresis = <1000>;
				type = "passive";
			};
		};
	};

	board-therm-usr {
		polling-delay-passive = <0>;
		polling-delay = <0>;
		thermal-governor = "user_space";
		thermal-sensors = <&pm8150_adc_tm ADC_GPIO1_PU2>;
		wake-capable-sensor;
		trips {
			active-config0 {
				temperature = <125000>;
				hysteresis = <1000>;
				type = "passive";
			};
		};
	};

	xo-therm-usr {
		polling-delay-passive = <0>;
		polling-delay = <0>;
		thermal-governor = "user_space";
		thermal-sensors = <&pm8150_adc_tm ADC_XO_THERM_PU2>;
		wake-capable-sensor;
		trips {
			active-config0 {
				temperature = <125000>;
				hysteresis = <1000>;
				type = "passive";
			};
		};
	};

	wcn-therm-usr {
		polling-delay-passive = <0>;
		polling-delay = <0>;
		thermal-governor = "user_space";
		thermal-sensors = <&pm8150_adc_tm ADC_AMUX_THM1_PU2>;
		wake-capable-sensor;
		trips {
			active-config0 {
				temperature = <125000>;
				hysteresis = <1000>;
				type = "passive";
			};
		};
	};

	batt-con-therm-usr {
		polling-delay-passive = <0>;
		polling-delay = <0>;
		thermal-governor = "user_space";
		thermal-sensors = <&pm8150_adc_tm ADC_AMUX_THM2_PU2>;
		wake-capable-sensor;
		trips {
			active-config0 {
				temperature = <125000>;
				hysteresis = <1000>;
				type = "passive";
			};
		};
	};

	camer-fl-therm-usr {
		polling-delay-passive = <0>;
		polling-delay = <0>;
		thermal-governor = "user_space";
		thermal-sensors = <&pm8150l_adc_tm ADC_AMUX_THM1_PU2>;
		wake-capable-sensor;
		trips {
			active-config0 {
				temperature = <125000>;
				hysteresis = <1000>;
				type = "passive";
			};
		};
	};
// #endif

	sdm-skin-therm-usr {
		polling-delay-passive = <0>;
		polling-delay = <0>;
		thermal-governor = "user_space";
		thermal-sensors = <&pm8150l_adc_tm ADC_AMUX_THM2_PU2>;
		wake-capable-sensor;
		trips {
			active-config0 {
				temperature = <125000>;
				hysteresis = <1000>;
				type = "passive";
			};
		};
	};

	sc_mos_temp-usr {
		polling-delay-passive = <0>;
		polling-delay = <0>;
		thermal-governor = "user_space";
		thermal-sensors = <&pm8150l_adc_tm ADC_AMUX_THM3_PU2>;
		wake-capable-sensor;
		trips {
			active-config0 {
				temperature = <125000>;
				hysteresis = <1000>;
				type = "passive";
			};
		};
	};

	skin-msm-therm-usr {
		polling-delay-passive = <0>;
		polling-delay = <0>;
		thermal-governor = "user_space";
		thermal-sensors = <&pm8150_adc_tm ADC_GPIO1_PU2>;
		wake-capable-sensor;
		trips {
			active-config0 {
				temperature = <125000>;
				hysteresis = <1000>;
				type = "passive";
			};
		};
	};

};

&sdhc_2 {
	vdd-supply = <&pm8150a_l9>;
	qcom,vdd-voltage-level = <2800000 2960000>;
	qcom,vdd-current-level = <200 800000>;

	vdd-io-supply = <&pm8150a_l6>;
	qcom,vdd-io-voltage-level = <1808000 2960000>;
	qcom,vdd-io-current-level = <200 22000>;

	pinctrl-names = "active", "sleep";
	pinctrl-0 = <&sdc2_clk_on  &sdc2_cmd_on &sdc2_data_on &storage_cd>;
	pinctrl-1 = <&sdc2_clk_off &sdc2_cmd_off &sdc2_data_off &storage_cd>;

	cd-gpios = <&tlmm 77 GPIO_ACTIVE_LOW>;
	status = "disabled";

};

&usb1 {
	extcon = <&extcon_usb1>;
};

&wil6210 {
	status = "disabled";
};

&pm8150_gpios {
	dischg_enable: dischg_enable {
		pins = "gpio10"; /* GPIO 10 */
		function = "normal"; /* normal */
		bias-disable; //No Pull
		power-source = <0>;//VIN0 3.3
		output-high; //digital output, no invert
		qcom,drive-strength = <3>; //LOW strength
		//drive-push-pull;//CMOS
	};

	dischg_disable: dischg_disable {
		pins = "gpio10"; /* GPIO 10 */
		function = "normal"; /* normal */
		bias-disable; //No Pull
		power-source = <0>;//VIN0 3.3
		output-low; //digital output, no invert
		qcom,drive-strength = <3>; //LOW strength
		//drive-push-pull;//CMOS
	};
	gpio3_adc {
		gpio3_adc_default: gpio3_adc_default {
		pins = "gpio3"; /* GPIO 3 */
		function = "normal"; /* normal */
		bias-high-impedance; /* DISABLE GPIO3 for ADC*/
		};
	};
};

&qupv3_se5_i2c {
	status = "okay";
	qcom,clk-freq-out = <400000>;
	qcom,noise-rjct-scl = <3>;
	qcom,noise-rjct-sda = <3>;

	/*
	mp2650-charger@5c {
		status = "disabled";
		compatible = "oplus,mp2650-charger";
		reg = <0x5c 0>;

		qcom,mps_otg_en-gpio = <&pm8150_gpios 3 0x00>;
		pinctrl-names = "mps_otg_en_active", "mps_otg_en_sleep", "mps_otg_en_default";
		pinctrl-0 = <&mps_otg_en_active>;
		pinctrl-1 = <&mps_otg_en_sleep>;
		pinctrl-2 = <&mps_otg_en_default>;

	};
	*/
	KTZ8866@11 {
		compatible = "ktz,ktz8866";
		reg = <0x11>;
		ktz8866_hw_en = <&tlmm 62 0>;
	};
};
//#endif


&pm8150b_charger {
			//for 21027
			//for smb5:
			qcom,usb-icl-ua = <2000000>;
			qcom,fcc-max-ua = <3000000>;
			//qcom,fv-max-uv = <4373000>;
			qcom,qc3-disable;
			qcom,hvdcp-disable;
			qcom,smart_charging_screenoff;
			//io-channels = <&pm8150b_vadc ADC_GPIO3>;
			//io-channel-names = "chgID_voltage_adc";
			//qcom,otg-cl-ua = <2000000>;
			qcom,float-option = <1>;
			qcom,oplus-pps-usbpd-detection = <&pm8150b_pdphy>;

			//for oplus chg framework:
			qcom,input_current_charger_ma = <2000>;
			qcom,pd_input_current_charger_ma = <2000>;
			qcom,qc_input_current_charger_ma = <2000>;

			qcom,input_current_usb_ma = <500>;

			qcom,input_current_cdp_ma = <1500>;
			qcom,input_current_led_ma = <1200>;
			qcom,input_current_led_ma_high = <1500>;
			qcom,input_current_led_ma_warm = <1800>;
			qcom,input_current_led_ma_normal = <2000>;
			qcom,led_warm_bat_decidegc = <350>;
			qcom,led_high_bat_decidegc = <370>;

			qcom,input_current_camera_ma = <1200>;

			qcom,input_current_vooc_led_ma_high = <1200>;
			qcom,input_current_vooc_led_ma_warm = <1800>;
			qcom,input_current_vooc_led_ma_normal = <3600>;
			qcom,input_current_vooc_ma_normal = <3600>;
			qcom,vooc_temp_bat_normal_decidegc = <350>;
			qcom,input_current_vooc_ma_warm = <3200>;
			qcom,vooc_temp_bat_warm_decidegc = <370>;
			qcom,input_current_vooc_ma_high = <2200>;
			qcom,vooc_temp_bat_hot_decidegc = <440>;

			qcom,charger_current_vooc_ma_normal = <1800>;

			qcom,chg_ctrl_by_calling;
			qcom,input_current_calling_ma = <1500>;
			//qcom,input_current_led_ma_overtemp = <900>;
			qcom,overtemp_bat_decidegc = <350>;
			qcom,iterm_disabled = <0>;
			qcom,iterm_ma = <418>;
			qcom,recharge-mv = <100>;
			qcom,batt_capacity_mah = <8360>;/*typical capacity*/
			//qcom,batt_capacity_mah = <4400>; /*rated capacity*/

			qcom,removed_bat_decidegc = <190>;  /*<-19C*/

			qcom,cold_bat_decidegc = <100>;  /*-10C~0C*/
			qcom,temp_cold_vfloat_mv = <4435>;
			qcom,temp_cold_fastchg_current_ma = <1600>;
			qcom,temp_cold_fastchg_current_ma_high = <1600>;
			qcom,temp_cold_fastchg_current_ma_low = <1200>;
			qcom,pd_temp_cold_fastchg_current_ma_high = <1600>;
			qcom,pd_temp_cold_fastchg_current_ma_low = <1200>;
			qcom,qc_temp_cold_fastchg_current_ma_high = <1600>;
			qcom,qc_temp_cold_fastchg_current_ma_low = <1200>;

			qcom,little_cold_bat_decidegc = <0>;	/*0C~5C*/
			qcom,temp_little_cold_vfloat_mv = <4435>;
			qcom,temp_little_cold_fastchg_current_ma_high = <2200>;
			qcom,temp_little_cold_fastchg_current_ma_low = <2000>;
			qcom,temp_little_cold_fastchg_current_ma = <2200>;
			qcom,pd_temp_little_cold_fastchg_current_ma_high = <3000>;
			qcom,pd_temp_little_cold_fastchg_current_ma_low = <2000>;
			qcom,qc_temp_little_cold_fastchg_current_ma_high = <3000>;
			qcom,qc_temp_little_cold_fastchg_current_ma_low = <2000>;

			qcom,cool_bat_decidegc = <50>;	/*5C~12C*/
			qcom,temp_cool_vfloat_mv = <4435>;
			qcom,temp_cool_fastchg_current_ma_high = <2200>;
			qcom,temp_cool_fastchg_current_ma_low = <2200>;
			qcom,pd_temp_cool_fastchg_current_ma_high = <3000>;
			qcom,pd_temp_cool_fastchg_current_ma_low = <3000>;
			qcom,qc_temp_cool_fastchg_current_ma_high = <3000>;
			qcom,qc_temp_cool_fastchg_current_ma_low = <3000>;

			qcom,little_cool_bat_decidegc = <120>;	/*12C~16C*/
			qcom,temp_little_cool_vfloat_mv = <4435>;
			qcom,temp_little_cool_fastchg_current_ma = <2200>;
			qcom,pd_temp_little_cool_fastchg_current_ma = <3000>;
			qcom,qc_temp_little_cool_fastchg_current_ma = <3000>;

			qcom,normal_bat_decidegc = <160>;	/*16C~45C*/
			qcom,temp_normal_fastchg_current_ma = <2200>;
			qcom,temp_normal_vfloat_mv = <4435>;
			qcom,pd_temp_normal_fastchg_current_ma = <3000>;
			qcom,qc_temp_normal_fastchg_current_ma = <3000>;

			qcom,warm_bat_decidegc = <450>;		/*45C~53C*/ /*8pin Bat Vooc project need add 3 degree C*/
			qcom,temp_warm_vfloat_mv = <4130>;
			qcom,temp_warm_fastchg_current_ma = <2000>;
			qcom,pd_temp_warm_fastchg_current_ma = <1000>;
			qcom,qc_temp_warm_fastchg_current_ma = <1000>;
			qcom,temp_warm_fastchg_current_ma_led_on = <1000>;

			qcom,hot_bat_decidegc = <530>;

			qcom,non_standard_vfloat_mv = <3980>;
			qcom,non_standard_fastchg_current_ma = <512>;

			qcom,short_c_bat_cv_mv = <4330>;
			qcom,short_c_bat_vfloat_mv = <3800>;
			qcom,short_c_bat_fastchg_current_ma = <512>;

			qcom,cold_vfloat_sw_limit = <4385>;
			qcom,little_cold_vfloat_sw_limit = <4385>;
			qcom,cool_vfloat_sw_limit = <4385>;
			qcom,little_cool_vfloat_sw_limit = <4385>;
			qcom,normal_vfloat_sw_limit = <4385>;
			qcom,warm_vfloat_sw_limit = <4080>;
			qcom,non_standard_vfloat_sw_limit = <3930>;
			qcom,short_c_bat_vfloat_sw_limit = <3750>;

			qcom,max_chg_time_sec = <36000>;
			qcom,charger_hv_thr = <9900>;
			qcom,charger_recv_thr = <9500>;
			qcom,charger_lv_thr = <3400>;
			qcom,vbatt_full_thr = <4435>;
			qcom,vbatt_hv_thr = <4600>;
			qcom,vfloat_step_mv = <8>;
			qcom,non_standard_vfloat_over_sw_limit = <3990>;
			qcom,cold_vfloat_over_sw_limit = <4445>;
			qcom,little_cold_vfloat_over_sw_limit = <4445>;
			qcom,cool_vfloat_over_sw_limit = <4445>;
			qcom,little_cool_vfloat_over_sw_limit = <4445>;
			qcom,normal_vfloat_over_sw_limit = <4445>;
			qcom,warm_vfloat_over_sw_limit = <4140>;

			qcom,vbatt_power_off = <3300>;
			qcom,vbatt_soc_1 = <3410>;
			qcom,vooc_project = <5>;
			qcom,vbatt_num = <1>;
			qcom,ffc_support;
			qcom,dual_ffc;
			//recharge_after_full;

			qcom,normal_vterm_hw_inc = <18>;
			qcom,non_normal_vterm_hw_inc = <18>;

			qcom,ff1_normal_fastchg_ma = <1500>;
			qcom,ff1_warm_fastchg_ma = <1700>;
			qcom,ffc2_normal_fastchg_ma = <1300>;/*12C~35c*/
			qcom,ffc2_temp_warm_decidegc = <350>;
			qcom,ffc2_warm_fastchg_ma = <1700>;/*35C~40c*/
			qcom,ffc2_temp_high_decidegc = <400>;
			qcom,ffc2_temp_low_decidegc = <120>;
			qcom,ffc2_exit_step_ma = <1100>;
			qcom,ff1_exit_step_ma = <1100>;
			qcom,ff1_warm_exit_step_ma = <1500>;

			qcom,ffc_normal_vfloat_sw_limit = <4465>;
			qcom,ffc2_normal_vfloat_sw_limit = <4465>;
			qcom,ffc2_warm_vfloat_sw_limit = <4465>;

			qcom,ffc_temp_normal_vfloat_mv = <4550>;
			qcom,ffc1_temp_normal_vfloat_mv = <4550>;
			qcom,ffc2_temp_normal_vfloat_mv = <4550>;
			qcom,ffc_normal_vfloat_over_sw_limit = <4650>;
			qcom,ffc1_normal_vfloat_over_sw_limit = <4650>;
			qcom,ffc2_normal_vfloat_over_sw_limit = <4650>;

			qcom,default_iterm_ma = <418>;
			qcom,default_temp_normal_fastchg_current_ma = <2200>;
			qcom,default_normal_vfloat_sw_limit = <4385>;
			qcom,default_temp_normal_vfloat_mv = <4435>;
			qcom,default_normal_vfloat_over_sw_limit = <4445>;

			qcom,default_temp_little_cool_fastchg_current_ma = <2200>;
			qcom,default_little_cool_vfloat_sw_limit = <4385>;
			qcom,default_temp_little_cool_vfloat_mv = <4435>;
			qcom,default_little_cool_vfloat_over_sw_limit = <4445>;

			///qcom,offset_temp = <30>;
			//for control:
			//qcom,suspend_after_full;
			qcom,check_batt_full_by_sw;
			//qcom,external_gauge;
			qcom,chg_ctrl_by_lcd;
			//qcom,chg_ctrl_by_vooc;
			qcom,chg_ctrl_by_camera;
			qcom,sw_vfloat_over_protect_enable;
			qcom,lpd-disable;
			qcom,usbtemp_batttemp_gap = <12>;
			qcom,voocphy_support = <2>;

			//for PD9V or QC9V
			qcom,vbatt_pdqc_to_5v_thr = <4500>;
                        qcom,vbatt_pdqc_to_9v_thr = <4500>;

			qcom,vooc_show_ui_soc_decimal;
			qcom,ui_soc_decimal_speedmin = <20>;//2A

			qcom,chargerid_switch-gpio = <&tlmm 48 0x00>;
			//qcom,ship-gpio = <&tlmm 22 0x00>;
			qcom,ccdetect-gpio = <&tlmm 14 0x00>;
			//qcom,shortc-gpio = <&tlmm 43 0x00>;
			qcom,dischg-gpio = <&pm8150_gpios 10 0x00>;
			//qcom,charger_int-gpio = <&tlmm 15 0x00>;
			//qcom,input_pg-gpio = <&tlmm 6 0x00>;
			//qcom,charger_error-gpio = <&tlmm 118 0x00>;

			pinctrl-names = "ccdetect_active", "ccdetect_sleep",
							"dischg_enable", "dischg_disable","gpio3_adc_default",
							"chargerid_switch_active", "chargerid_switch_sleep", "chargerid_switch_default";


			//pinctrl-0 = <&gpio1_adc_default>;
			pinctrl-0 = <&ccdetect_active>;
			pinctrl-1 = <&ccdetect_sleep>;
			pinctrl-2 = <&dischg_enable>;
			pinctrl-3 = <&dischg_disable>;
			pinctrl-4 = <&gpio3_adc_default>;
			pinctrl-5 = <&chargerid_switch_active>;
			pinctrl-6 = <&chargerid_switch_sleep>;
			pinctrl-7 = <&chargerid_switch_default>;
			screen_off_control_by_batt_temp;
};
//#endif //OPLUS_FEATURE_CHG_BASIC

